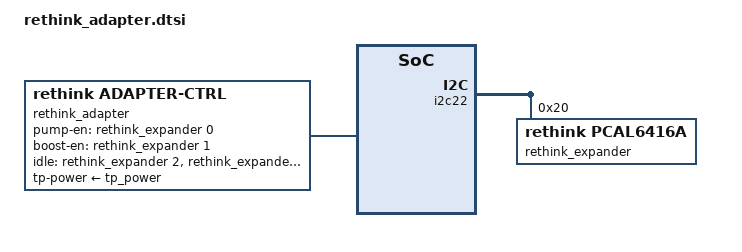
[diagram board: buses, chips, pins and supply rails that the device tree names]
/*
 * Copyright (c) 2026 Ziemniaczenka
 * SPDX-License-Identifier: MIT
 *
 * ReThink adapter v1.0: PCAL6416A (U1, 0x20) on the touchpad I2C bus.
 * Include after rethink_cb.dtsi. Pin map: ReThink_keyboard
 * docs/pinouts/io_expander.md.
 *
 * Shields add what their keyboard has to &rethink_adapter: the status LEDs
 * (pwr/mute/micmute/capslock/numlock-led-gpios) and bl-detect-gpios. Backlit
 * keyboards also include rethink_backlight.dtsi.
 *
 * Jumpers and fitted parts are Kconfig options (config/rethink.conf).
 */

&i2c22 {
    // Probed and driven by rethink,adapter-ctrl; absent on a bare Control Board
    rethink_expander: gpio@20 {
        compatible = "rethink,pcal6416a";
        reg = <0x20>;
        #gpio-cells = <2>;
    };
};

/ {
    rethink_adapter: rethink_adapter {
        compatible = "rethink,adapter-ctrl";
        expander = <&rethink_expander>;
        tp-power-supply = <&tp_power>;
        pump-en-gpios = <&rethink_expander 0 GPIO_ACTIVE_HIGH>;
        boost-en-gpios = <&rethink_expander 1 GPIO_ACTIVE_HIGH>;
        // Every pin except the enables, which JP1/JP2 may tie to TP_3V3/VIN.
        // Keyboard lines are open or switch to GND, LED lines go to LEDs from
        // LED_3V3: the pull-ups draw nothing at rest. TP1/TP2_RST: R14/R22
        // pull them to TP1/TP2_PWR, which float while off (TP2_RST drew
        // ~100 µA in System OFF); the pull-downs cost 30-45 µA through R14/R22
        // only while the pointing stick is powered, and agree with R23.
        // A shield whose keyboard holds one of these low replaces the list,
        // with that pin on GPIO_PULL_DOWN (33 µA saved): T60 Mezzanine 36 on
        // LEDMICMUTE is GND; check KBD_ID (DRV16) on the T480.
        idle-gpios = <&rethink_expander 2 GPIO_PULL_UP>,  // P0_2 HOTKEY
                     <&rethink_expander 3 GPIO_PULL_UP>,  // P0_3 PWRSWITCH
                     <&rethink_expander 4 GPIO_PULL_UP>,  // P0_4 DRV15
                     <&rethink_expander 5 GPIO_PULL_UP>,  // P0_5 DRV16
                     <&rethink_expander 6 GPIO_PULL_UP>,  // P0_6 DRV17
                     <&rethink_expander 7 GPIO_PULL_UP>,  // P0_7 OUT1 (J9)
                     <&rethink_expander 8 GPIO_PULL_DOWN>, // P1_0 TP1_RST
                     <&rethink_expander 9 GPIO_PULL_DOWN>, // P1_1 TP2_RST
                     <&rethink_expander 10 GPIO_PULL_UP>, // P1_2 LEDPWR
                     <&rethink_expander 11 GPIO_PULL_UP>, // P1_3 LEDMUTE
                     <&rethink_expander 12 GPIO_PULL_UP>, // P1_4 LEDMICMUTE
                     <&rethink_expander 13 GPIO_PULL_UP>, // P1_5 LEDCPSLOCK
                     <&rethink_expander 14 GPIO_PULL_UP>, // P1_6 LEDNUMLOCK
                     <&rethink_expander 15 GPIO_PULL_UP>; // P1_7 KBD_BL_DTCT
    };
};

// U1 pins for the shields
#define RETHINK_EXP_LEDPWR 10      // P1_2, power LED (Mezzanine) / Fn lock (FFC2)
#define RETHINK_EXP_LEDMUTE 11     // P1_3
#define RETHINK_EXP_LEDMICMUTE 12  // P1_4
#define RETHINK_EXP_LEDCPSLOCK 13  // P1_5, also KBD_BL_DTCT on the T430 (Mezzanine 21)
#define RETHINK_EXP_LEDNUMLOCK 14  // P1_6
#define RETHINK_EXP_KBD_BL_DTCT 15 // P1_7, FFC2 12-pin connector
